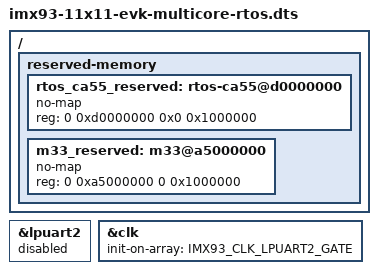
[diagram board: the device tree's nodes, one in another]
// SPDX-License-Identifier: (GPL-2.0 OR MIT)
/*
 * Copyright 2023-2024 NXP
 */

/dts-v1/;
#include "imx93-11x11-evk.dts"
#include "imx93-rproc-ca55.dtsi"

/ {
	reserved-memory {
		#address-cells = <2>;
		#size-cells = <2>;
		ranges;

		/*
		 * Reserve up to 16MB for one possible FreeRTOS instances running on
		 * one Cortex-A Cores when booting Linux on at least on Cortex-A Core.
		 */
		rtos_ca55_reserved: rtos-ca55@d0000000 {
			no-map;
			reg = <0 0xd0000000 0x0 0x1000000>;
		};

		/* Reserve 16MB for FreeRTOS on M33 */
		m33_reserved: m33@a5000000 {
			no-map;
			reg = <0 0xa5000000 0 0x1000000>;
		};
	};
};

&lpuart2 {
	status = "disabled";
};

&clk {
	init-on-array = <IMX93_CLK_LPUART2_GATE>;
};
